# HK32F030xMxxA register map
Vendor: HKMicroChip Ltd.; Series: HK32F030xMxxA; File version: 0.9
Arm 32-bit CCortex-M0 Microcontroller based device, CPU clock up to 48 MHz
CPU: CM0 r0p0, little endian, no MPU, no FPU, 3 interrupt priority bits
Registers are 32-bit, read-write, reset 0x0 unless marked. A register's access mark holds for its fields unless they carry their own. Offsets are from the block's base; lines under a group give offsets from that group; [hi:lo] are bit positions; {n}, {i} and the like mark numbered series; 'fields as' and 'values as' point back to an identical list; <NAME> marks a mode.

## Memory map
0x40000000 TIM2 size 0x400
0x40001000 TIM6 size 0x400
0x40002C00 WWDG size 0x400
0x40003000 IWDG size 0x400
0x40005400 I2C size 0x400
0x40007000 PWR size 0x400
0x40007800 AWUT size 0x400
0x40007C00 BEEP size 0x400
0x40010000 SYSCFG size 0x400
0x40010400 EXTI size 0x400
0x40012400 ADC size 0x400
0x40012C00 TIM1 size 0x400
0x40013000 SPI size 0x400
0x40013800 USART1 size 0x400
0x40013C00 UART2 size 0x400
0x40014000 UART3 size 0x400
0x40014400 UART4 size 0x400
0x40015800 DBGMCU size 0x400
0x40017C00 IOMUX size 0x400
0x40021000 RCC size 0x400
0x40022000 FLASH size 0x400
0x40023000 CRC size 0x400
0x48000000 GPIOA size 0x400
0x48000400 GPIOB size 0x400
0x48000800 GPIOC size 0x400
0x48000C00 GPIOD size 0x400

## Interrupts
0 WWDG — Window Watchdog interrupt
2 EXTI11 (EXTI) — AWUT_WKP
3 FLASH — FLASH global interrupt
4 RCC — RCC global interrupt
5 EXTI0 (EXTI) — EXTI Line0 interrupt
6 EXTI1 (EXTI) — EXTI Line1 interrupt
7 EXTI2 (EXTI) — EXTI Line2 interrupt
8 EXTI3 (EXTI) — EXTI Line3 interrupt
9 EXTI4 (EXTI) — EXTI Line4 interrupt
10 EXTI5 (EXTI) — EXTI Line5 interrupt
11 TIM1_BRK (TIM1) — TIM1 Break interrupt
12 ADC1 (ADC) — ADC interrupt, combined with EXTI Line8
13 TIM1_UP_TRG_COM (TIM1) — TIM1 Update/Trigger interrupt
14 TIM1_CC (TIM1) — TIM1 Capture /Compare interrupt
15 TIM2 (TIM1) — TIM2 global interrupt
17 TIM6 (TIM1) — TIM6 global interrupt
21 EXTI6 (EXTI) — EXTI Line6 interrupt
22 EXTI7 (EXTI) — EXTI Line7 interrupt
23 I2C — I2C global interrupt, combined with EXTI Line 10
25 SPI — SPI global interrupt
27 USART1 — USART1 global interrupt, combined with EXTI Line9
28 UART2 (FLASH) — UART2 global interrupt
29 UART3 (FLASH) — UART3 global interrupt
30 UART4 (FLASH) — UART4 global interrupt

## FLASH
Base 0x40022000
0x00 ACR
  [2:0] LATENCY
0x04 KEYR wo
  [31:0] FKEYR — FLASH key
0x08 OPTKEYR wo
  [31:0] OPTKEYR — Option byte key
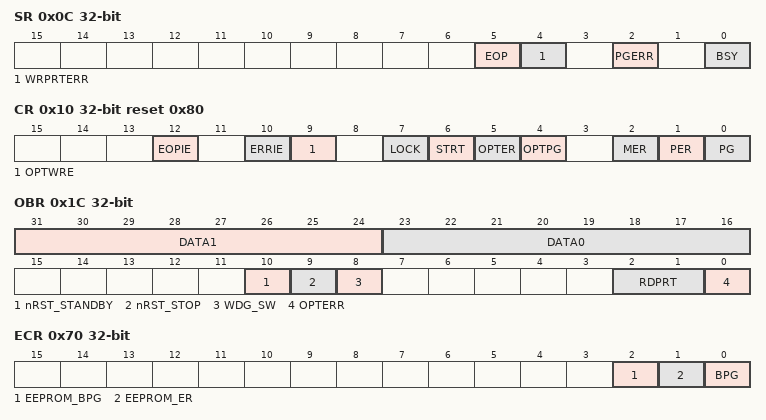
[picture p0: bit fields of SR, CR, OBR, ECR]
0x0C SR access per field
  [5] EOP rw — End of operation
  [4] WRPRTERR rw — Write protection error
  [2] PGERR rw — Programming error
  [0] BSY ro — Busy
0x10 CR reset 0x80
  [12] EOPIE — End of operation interrupt enable
  [10] ERRIE — Error interrupt enable
  [9] OPTWRE — Option byte write enable
  [7] LOCK
  [6] STRT — Start
  [5] OPTER — Option byte erase
  [4] OPTPG — Option byte program
  [2] MER — Main Flash Mass erase
  [1] PER — Main Flash Page erase
  [0] PG — Main Flash Halfword Program
0x14 AR wo
  [31:0] FAR — FLASH Address
0x1C OBR ro
  [31:24] DATA1 — User data
  [23:16] DATA0 — User data
  [10] nRST_STANDBY — Enter the standby mode for a reset
  [9] nRST_STOP — Enter the stop mode for a reset
  [8] WDG_SW — Select a software or hardware watchdog
  [2:1] RDPRT — Read protection level status
  [0] OPTERR — Option byte error
0x20 WRPR ro
  [31:0] WRP — Write protect
0x70 ECR
  [2] EEPROM_BPG — EEPROM program by Byte
  [1] EEPROM_ER — EEPROM erase by Byte
  [0] BPG — Main flash Program by Byte
0x74 INT_VEC_OFFSET reset 0x4 — Interruput Vector table address offset register
  [13:0] INT_VEC_OFFSET — Interrupt Vector table address Offset

## CRC
Base 0x40023000
0x00 DR reset 0xFFFFFFFF
  [31:0] DR — Data register
0x04 IDR
  [7:0] IDR — General purpose 8-bit data register
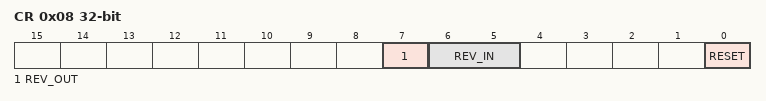
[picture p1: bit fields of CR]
0x08 CR
  [7] REV_OUT — Output data revert
  [6:5] REV_IN — Input data revert
  [0] RESET — Reset control
0x10 INIT reset 0xFFFFFFFF
  [31:0] CRC_INIT — CRC initiate value

## Licence text in the file
HKMicroChip Limited (HKMicroChip) is supplying this software for use with Cortex-M0!
